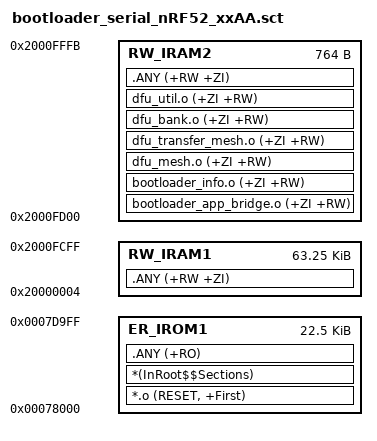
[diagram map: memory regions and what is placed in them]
; *************************************************************
; *** Scatter-Loading Description File generated by uVision ***
; *************************************************************

LR_IROM1 0x00078000 0x00005A00  {    ; load region size_region
  ER_IROM1 0x00078000 0x00005A00  {  ; load address = execution address
   *.o (RESET, +First)
   *(InRoot$$Sections)
   .ANY (+RO)
  }

  RW_IRAM1 0x20000004 0x0000FCFC  {  ; RW data
   .ANY (+RW +ZI)
  }

  RW_IRAM2 0x2000FD00 0x000002FC  {
    ;sha256.o (+ZI +RW)
    bootloader_app_bridge.o (+ZI +RW)
    bootloader_info.o (+ZI +RW)
    ;uECC.o (+ZI +RW)
    dfu_mesh.o (+ZI +RW)
    dfu_transfer_mesh.o (+ZI +RW)
    dfu_bank.o (+ZI +RW)
    dfu_util.o (+ZI +RW)
   .ANY (+RW +ZI)
  }
}

